# VPE_VPDMA register map
Vendor: Texas Instruments
Registers are 32-bit, access per field, reset 0x0 unless marked. A register's access mark holds for its fields unless they carry their own. Offsets are as the file gives them; [hi:lo] are bit positions; {n}, {i} and the like mark numbered series.

## VPE_VPDMA (part 2 of 3)
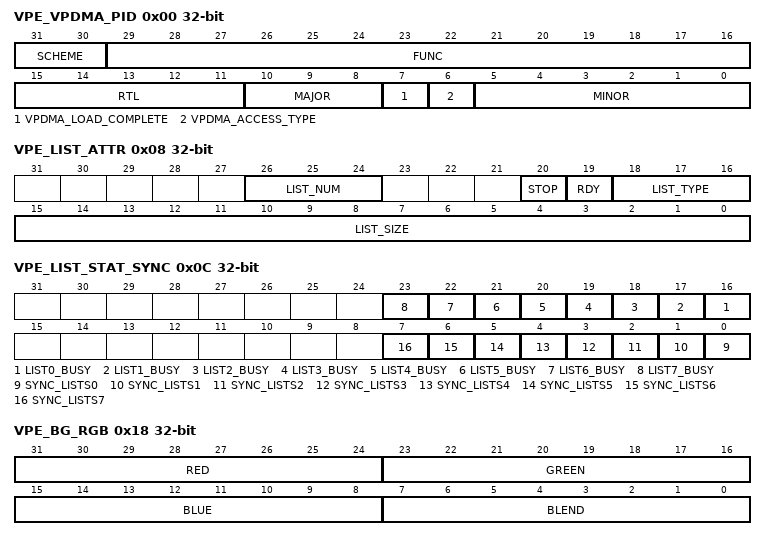
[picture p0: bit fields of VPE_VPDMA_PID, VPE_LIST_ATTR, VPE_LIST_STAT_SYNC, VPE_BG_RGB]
0x00 VPE_VPDMA_PID ro — This register follows the format described in PDR3.5
  [31:30] SCHEME — The scheme of the register used. Currently this is PDR 3.5 Scheme
  [29:16] FUNC — The funcition of the module being used. The value is for vpe0_vayu_vpdma.
  [15:11] RTL — RTL Release Version The PDR release number of this IP. After Bootup this value becomes the firmware Revision ID
  [10:8] MAJOR — Major Release Number
  [7] VPDMA_LOAD_COMPLETE — This bit will be 1 when the VPDMA state machines image and data image have successfuly been fetched and loaded.
  [6] VPDMA_ACCESS_TYPE — After bootup this bit states how DMA transaction are setup by lists or through register access.
    0=Lists; 1=Register_Access
  [5:0] MINOR — Minor Release Number
0x04 VPE_LIST_ADDR rw — The location of a new list to begin processing.
  [31:0] LIST_ADDR — Location of a new list of descriptors. This register must be written with the VPDMA Configuration Location after reset.
0x08 VPE_LIST_ATTR — The attributes of a new list. This register should always be written after list_addr.
  [26:24] LIST_NUM rw — The list number that should be assigned to the list located at LIST_ADDR. If the list is still active this will block all future list writes until the list is available.
  [20] STOP rw — This bit is written with the LIST_NUMBER field to stop a self-modifying list. When this bit is written a one the list specified by the LIST_NUMBER is sent a stop signal and will finish the current frame of transfers and then free the list resources.
  [19] RDY ro — This bit is low when a new list cannot be written to theVPE_LIST_ADDR register. The reasons this bit would be low are at initial startup if the LIST_MANAGER State Machine image has not completed loading. It also would be low if the last write to the LIST_ATTR attempted to start a list that is currently active. When this bit is low any writes to the list address register will cause access to not be accepted until this bit has set by the previous list having completed.
  [18:16] LIST_TYPE rw — The type of list that has been generated.
    0=Normal_List; 1=Self-Modifying_List; 2=List Doorbell Others Reserved for future use
  [15:0] LIST_SIZE rw — Number of 128 bit word in the new list of descriptors. Writes to this register will activate the list in the list stack of the list manager and begin transfer of the list into VPDMA. This size can not be 0.
0x0C VPE_LIST_STAT_SYNC — The register is used for processor to List Manager syncronization and status registers for the list.
  [n+16] LIST{n}_BUSY ro (n=0..7) — The list {n} is currently running. Any attempt to load a new list to list {n} will result in the LM_ADDR and LM_ATTR registers to be locked until the list is complete and this value goes to 0.
  [n] SYNC_LISTS{n} rw (n=0..7) — Writing a 1 to this field causes a sync event to fire that clears a Control Descriptor in List {n} waiting on it.
0x18 VPE_BG_RGB rw — The registers used to set the background color for RGB
  [31:24] RED — The red value to give on an RGB data port for a blank pixel when using virtual video buffering
  [23:16] GREEN — The green value to give on an RGB data port for a blank pixel when using virtual video buffering
  [15:8] BLUE — The blue value to give on an RGB data port for a blank pixel when using virtual video buffering
  [7:0] BLEND — The blend value to give on an RGB data port for a blank pixel when using virtual video buffering
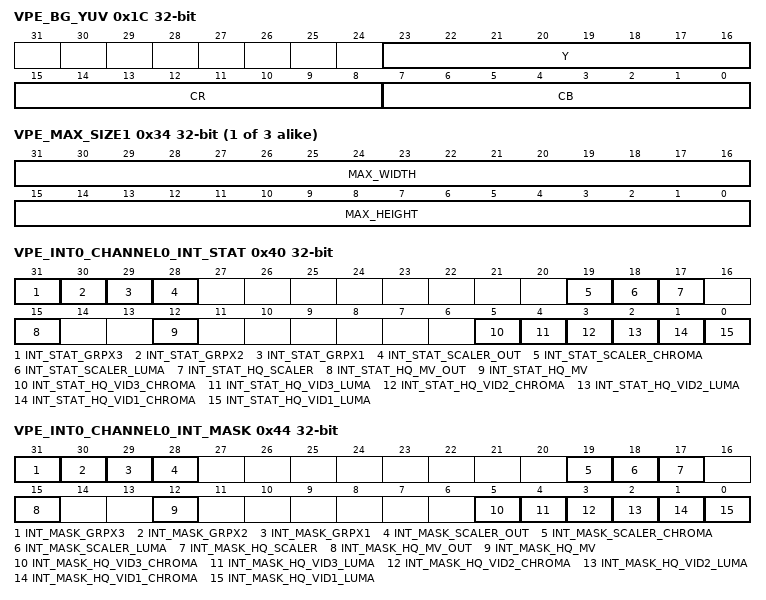
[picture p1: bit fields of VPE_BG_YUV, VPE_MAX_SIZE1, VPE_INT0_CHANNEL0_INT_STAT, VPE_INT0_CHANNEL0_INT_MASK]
0x1C VPE_BG_YUV — The registers used to set the background color for YUV
  [23:16] Y rw — The Y value to give on a YUV data port for a blank pixel when using virtual video buffering
  [15:8] CR rw — The Cr value to give on a YUV data port for a blank pixel when using virtual video buffering
  [7:0] CB rw — The Cb value to give on a YUV data port for a blank pixel when using virtual video buffering
0x30 VPE_VPDMA_SETUP — Configures global parameters that are shared by all clients.
  [0] SEC_BASE_CH rw — Use Secondary Channels for Mosaic mode
{0x30+4i} VPE_MAX_SIZE{i} rw (i=1..3) — Configures maximum width and maximum height global parameters that are shared by all clients to allow for configurable max width and max height when setting is {i} in write descriptor.
  [31:16] MAX_WIDTH — The maximum width to use for setting of max_width {i} in a write descriptor. The value is the number of pixels + 1 so if 1024 pixels are required then set the value to 1023.
  [15:0] MAX_HEIGHT — The maximum height to use for setting of max_height {i} in a write descriptor. The value is the number of lines + 1 so if 1024 lines are required then set the value to 1023.
0x40 VPE_INT0_CHANNEL0_INT_STAT — This register gives the information of the interrupts that have triggered since last cleared by the process that is servicing vpdma_int0.
  [31] INT_STAT_GRPX3 rw — The last read DMA transaction has occurred for channel grpx3 and the channel is free to be updated for the next transfer. This will fire before the destination has received the data as it will have just been stored in the internal buffer. The client grpx3_data will now accept a new descriptor from the List Manager. This event will cause a one to be set in this register until cleared by software. Write a 1 to this field to clear the value.
  [30] INT_STAT_GRPX2 rw — The last read DMA transaction has occurred for channel grpx2 and the channel is free to be updated for the next transfer. This will fire before the destination has received the data as it will have just been stored in the internal buffer. The client grpx2_data will now accept a new descriptor from the List Manager. This event will cause a one to be set in this register until cleared by software. Write a 1 to this field to clear the value.
  [29] INT_STAT_GRPX1 rw — The last read DMA transaction has occurred for channel grpx1 and the channel is free to be updated for the next transfer. This will fire before the destination has received the data as it will have just been stored in the internal buffer. The client grpx1_data will now accept a new descriptor from the List Manager. This event will cause a one to be set in this register until cleared by software. Write a 1 to this field to clear the value.
  [28] INT_STAT_SCALER_OUT rw — The last write DMA transaction has completed for channel scaler_out. All data from the channel has been sent and received by the external memory. If a new channel has not been setup for the client sc_out then the client will be fully empty at this point. This event will cause a one to be set in this register until cleared by software. Write a 1 to this field to clear the value
  [19] INT_STAT_SCALER_CHROMA rw — The last write DMA transaction has completed for channel scaler_chroma. All data from the channel has been sent and received by the external memory. If a new channel has not been setup for the client then the client will be fully empty at this point. This event will cause a one to be set in this register until cleared by software. Write a 1 to this field to clear the value.
  [18] INT_STAT_SCALER_LUMA rw — The last write DMA transaction has completed for channel scaler_luma. All data from the channel has been sent and received by the external memory. If a new channel has not been setup for the client then the client will be fully empty at this point. This event will cause a one to be set in this register until cleared by software. Write a 1 to this field to clear the value.
  [17] INT_STAT_HQ_SCALER rw — The last write DMA transaction has completed for channel hq_scaler. All data from the channel has been sent and received by the external memory. If a new channel has not been setup for the client dei_sc_out then the client will be fully empty at this point. This event will cause a one to be set in this register until cleared by software. Write a 1 to this field to clear the value.
  [15] INT_STAT_HQ_MV_OUT rw — The last write DMA transaction has completed for channel hq_mv_out. All data from the channel has been sent and received by the external memory. If a new channel has not been setup for the client dei_hq_mv_out then the client will be fully empty at this point. This event will cause a one to be set in this register until cleared by software. Write a 1 to this field to clear the value.
  [12] INT_STAT_HQ_MV rw — The last read DMA transaction has occurred for channel hq_mv and the channel is free to be updated for the next transfer. This will fire before the destination has received the data as it will have just been stored in the internal buffer. The client dei_hq_mv_in will now accept a new descriptor from the List Manager. This event will cause a one to be set in this register until cleared by software. Write a 1 to this field to clear the value.
  [5] INT_STAT_HQ_VID3_CHROMA rw — The last write DMA transaction has completed for channel hq_vid3_chroma. All data from the channel has been sent and received by the external memory. If a new channel has not been setup for the client then the client will be fully empty at this point. This event will cause a one to be set in this register until cleared by software. Write a 1 to this field to clear the value.
  [4] INT_STAT_HQ_VID3_LUMA rw — The last write DMA transaction has completed for channel hq_vid3_luma. All data from the channel has been sent and received by the external memory. If a new channel has not been setup for the client then the client will be fully empty at this point. This event will cause a one to be set in this register until cleared by software. Write a 1 to this field to clear the value.
  [3] INT_STAT_HQ_VID2_CHROMA rw — The last write DMA transaction has completed for channel hq_vid2_chroma. All data from the channel has been sent and received by the external memory. If a new channel has not been setup for the client then the client will be fully empty at this point. This event will cause a one to be set in this register until cleared by software. Write a 1 to this field to clear the value.
  [2] INT_STAT_HQ_VID2_LUMA rw — The last write DMA transaction has completed for channel hq_vid2_luma. All data from the channel has been sent and received by the external memory. If a new channel has not been setup for the client then the client will be fully empty at this point. This event will cause a one to be set in this register until cleared by software. Write a 1 to this field to clear the value.
  [1] INT_STAT_HQ_VID1_CHROMA rw — The last write DMA transaction has completed for channel hq_vid1_chroma. All data from the channel has been sent and received by the external memory. If a new channel has not been setup for the client then the client will be fully empty at this point. This event will cause a one to be set in this register until cleared by software. Write a 1 to this field to clear the value.
  [0] INT_STAT_HQ_VID1_LUMA rw — The last write DMA transaction has completed for channel hq_vid1_luma. All data from the channel has been sent and received by the external memory. If a new channel has not been setup for the client then the client will be fully empty at this point. This event will cause a one to be set in this register until cleared by software. Write a 1 to this field to clear the value.
0x44 VPE_INT0_CHANNEL0_INT_MASK — The register gives the information of the interrupts that should be masked and not generate an interrupt for vpdma_int0.
  [31] INT_MASK_GRPX3 rw — The interrupt for Graphcis 2 Data should generate an interrupt on interrupt vpdma_int0. Write a 1 for the interrupt event to trigger the interrupt signal.
  [30] INT_MASK_GRPX2 rw — The interrupt for Graphics 1 Data should generate an interrupt on interrupt vpdma_int0. Write a 1 for the interrupt event to trigger the interrupt signal.
  [29] INT_MASK_GRPX1 rw — The interrupt for Graphics 0 Data should generate an interrupt on interrupt vpdma_int0. Write a 1 for the interrupt event to trigger the interrupt signal.
  [28] INT_MASK_SCALER_OUT rw — The interrupt for Low Cost DEI Scalar Write to Memory should generate an interrupt on interrupt vpdma_int0. Write a 1 for the interrupt event to trigger the interrupt signal.
  [19] INT_MASK_SCALER_CHROMA rw — The interrupt for should generate an interrupt on interrupt vpdma_int0. Write a 1 for the interrupt event to trigger the interrupt signal.
  [18] INT_MASK_SCALER_LUMA rw — The interrupt for should generate an interrupt on interrupt vpdma_int0. Write a 1 for the interrupt event to trigger the interrupt signal.
  [17] INT_MASK_HQ_SCALER rw — The interrupt for High Quality DEI Scaler Write to Memory should generate an interrupt on interrupt vpdma_int0. Write a 1 for the interrupt event to trigger the interrupt signal.
  [15] INT_MASK_HQ_MV_OUT rw — The interrupt for Low Cost DEI Motion Vector Write should generate an interrupt on interrupt vpdma_int0. Write a 1 for the interrupt event to trigger the interrupt signal.
  [12] INT_MASK_HQ_MV rw — The interrupt for Low Cost DEI Motion Vector should generate an interrupt on interrupt vpdma_int0. Write a 1 for the interrupt event to trigger the interrupt signal.
  [5] INT_MASK_HQ_VID3_CHROMA rw — The interrupt for should generate an interrupt on interrupt vpdma_int0. Write a 1 for the interrupt event to trigger the interrupt signal.
  [4] INT_MASK_HQ_VID3_LUMA rw — The interrupt for should generate an interrupt on interrupt vpdma_int0. Write a 1 for the interrupt event to trigger the interrupt signal.
  [3] INT_MASK_HQ_VID2_CHROMA rw — The interrupt for should generate an interrupt on interrupt vpdma_int0. Write a 1 for the interrupt event to trigger the interrupt signal.
  [2] INT_MASK_HQ_VID2_LUMA rw — The interrupt for should generate an interrupt on interrupt vpdma_int0. Write a 1 for the interrupt event to trigger the interrupt signal.
  [1] INT_MASK_HQ_VID1_CHROMA rw — The interrupt for should generate an interrupt on interrupt vpdma_int0. Write a 1 for the interrupt event to trigger the interrupt signal.
  [0] INT_MASK_HQ_VID1_LUMA rw — The interrupt for should generate an interrupt on interrupt vpdma_int0. Write a 1 for the interrupt event to trigger the interrupt signal.
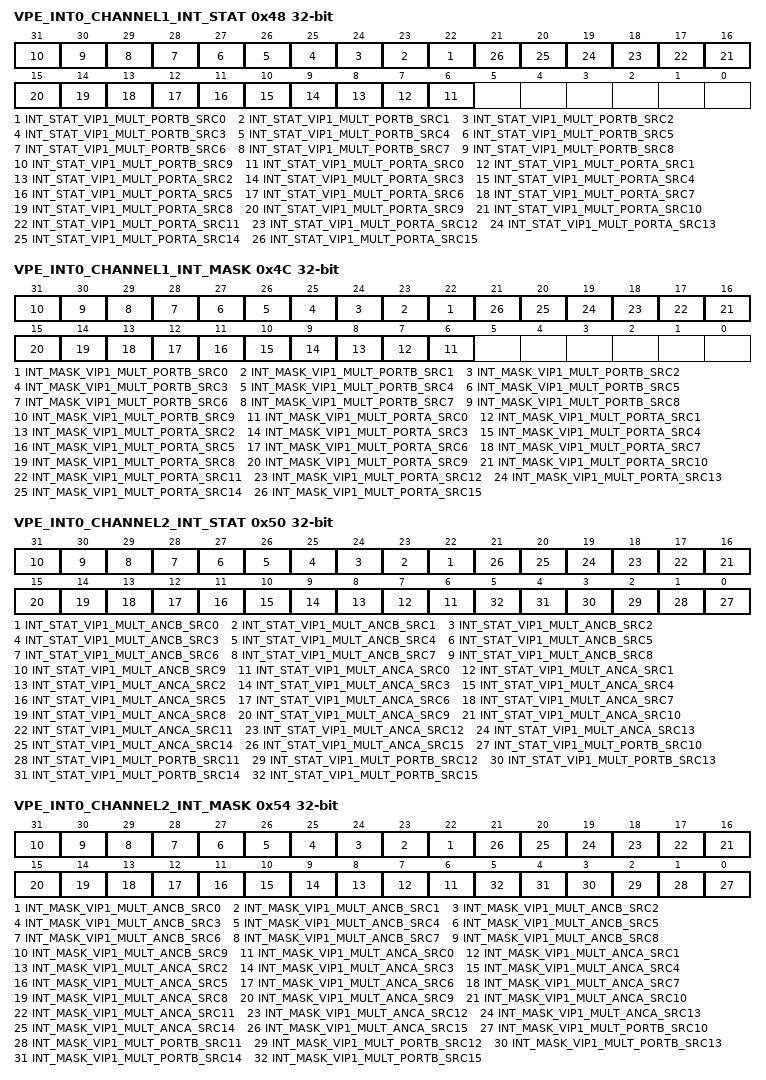
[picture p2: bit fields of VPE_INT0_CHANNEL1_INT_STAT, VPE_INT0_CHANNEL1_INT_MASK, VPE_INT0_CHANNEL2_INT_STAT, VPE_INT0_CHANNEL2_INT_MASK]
0x48 VPE_INT0_CHANNEL1_INT_STAT — This register gives the information of the interrupts that have triggered since last cleared by the process that is servicing vpdma_int0.
  [n+22] INT_STAT_VIP1_MULT_PORTB_SRC{n} rw (n=0..9) — The last write DMA transaction has completed for channel vip1_mult_portb_src{n}. All data from the channel has been sent and received by the external memory. If a new channel has not been setup for the client vip1_lo_uv then the client will be fully empty at this point. This event will cause a one to be set in this register until cleared by software. Write a 1 to this field to clear the value.
  [n+6] INT_STAT_VIP1_MULT_PORTA_SRC{n} rw (n=0..15) — The last write DMA transaction has completed for channel vip1_mult_porta_src{n}. All data from the channel has been sent and received by the external memory. If a new channel has not been setup for the client vip1_lo_y then the client will be fully empty at this point. This event will cause a one to be set in this register until cleared by software. Write a 1 to this field to clear the value.
0x4C VPE_INT0_CHANNEL1_INT_MASK — The register gives the information of the interrupts that should be masked and not generate an interrupt for vpdma_int0.
  [n+22] INT_MASK_VIP1_MULT_PORTB_SRC{n} rw (n=0..9) — The interrupt for Video Input 1 Port B Channel {n} should generate an interrupt on interrupt vpdma_int0. Write a 1 for the interrupt event to trigger the interrupt signal.
  [n+6] INT_MASK_VIP1_MULT_PORTA_SRC{n} rw (n=0..15) — The interrupt for Video Input 1 Port A Channel {n} should generate an interrupt on interrupt vpdma_int0. Write a 1 for the interrupt event to trigger the interrupt signal.
0x50 VPE_INT0_CHANNEL2_INT_STAT rw — This register gives the information of the interrupts that have triggered since last cleared by the process that is servicing vpdma_int0.
  [n+22] INT_STAT_VIP1_MULT_ANCB_SRC{n} (n=0..9) — The last write DMA transaction has completed for channel vip1_mult_ancb_src{n}. All data from the channel has been sent and received by the external memory. If a new channel has not been setup for the client vip1_anc_b then the client will be fully empty at this point. This event will cause a one to be set in this register until cleared by software. Write a 1 to this field to clear the value.
  [n+6] INT_STAT_VIP1_MULT_ANCA_SRC{n} (n=0..15) — The last write DMA transaction has completed for channel vip1_mult_anca_src{n}. All data from the channel has been sent and received by the external memory. If a new channel has not been setup for the client vip1_anc_a then the client will be fully empty at this point. This event will cause a one to be set in this register until cleared by software. Write a 1 to this field to clear the value.
  [n-10] INT_STAT_VIP1_MULT_PORTB_SRC{n} (n=10..15) — The last write DMA transaction has completed for channel vip1_mult_portb_src{n}. All data from the channel has been sent and received by the external memory. If a new channel has not been setup for the client vip1_lo_uv then the client will be fully empty at this point. This event will cause a one to be set in this register until cleared by software. Write a 1 to this field to clear the value.
0x54 VPE_INT0_CHANNEL2_INT_MASK rw — The register gives the information of the interrupts that should be masked and not generate an interrupt for vpdma_int0.
  [n+22] INT_MASK_VIP1_MULT_ANCB_SRC{n} (n=0..9) — The interrupt for Video Input 1 Port B Ancillary Data Channel {n} should generate an interrupt on interrupt vpdma_int0. Write a 1 for the interrupt event to trigger the interrupt signal.
  [n+6] INT_MASK_VIP1_MULT_ANCA_SRC{n} (n=0..15) — The interrupt for Video Input 1 Port A Ancillary Data Channel {n} should generate an interrupt on interrupt vpdma_int0. Write a 1 for the interrupt event to trigger the interrupt signal.
  [n-10] INT_MASK_VIP1_MULT_PORTB_SRC{n} (n=10..15) — The interrupt for Video Input 1 Port B Channel {n} should generate an interrupt on interrupt vpdma_int0. Write a 1 for the interrupt event to trigger the interrupt signal.
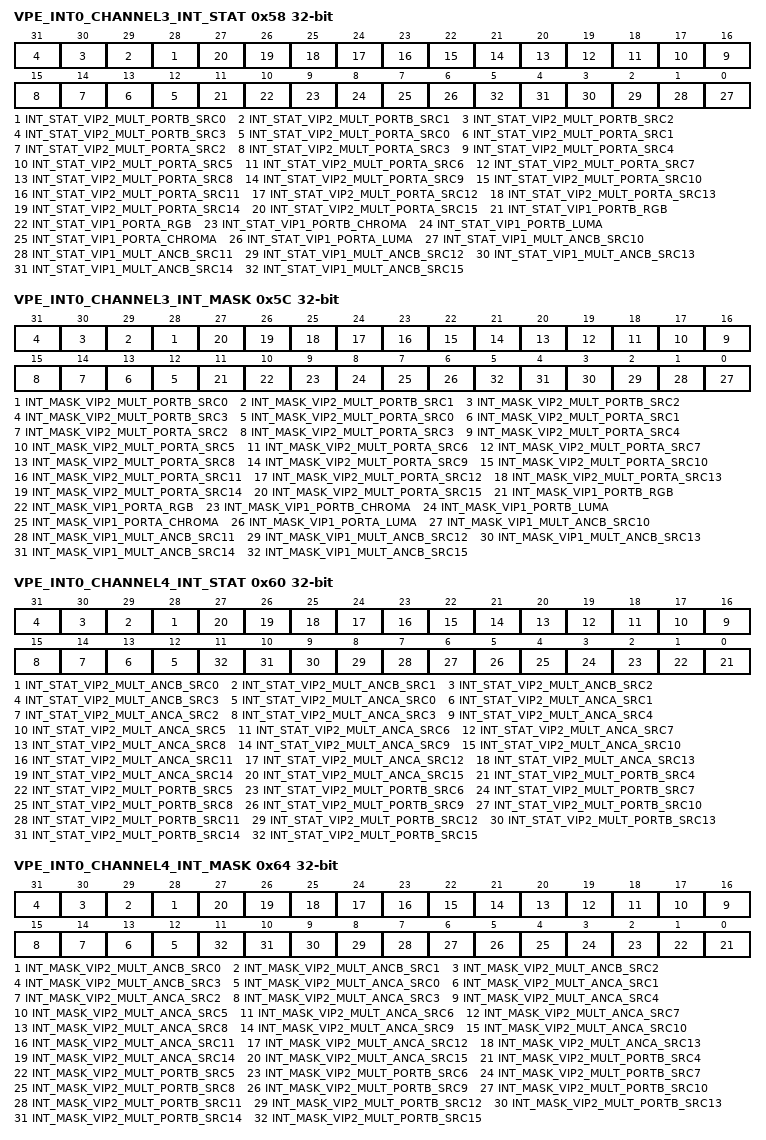
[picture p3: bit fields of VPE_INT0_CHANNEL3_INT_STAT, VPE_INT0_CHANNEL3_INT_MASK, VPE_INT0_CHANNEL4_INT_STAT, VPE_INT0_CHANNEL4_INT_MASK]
0x58 VPE_INT0_CHANNEL3_INT_STAT rw — This register gives the information of the interrupts that have triggered since last cleared by the process that is servicing vpdma_int0.
  [n+28] INT_STAT_VIP2_MULT_PORTB_SRC{n} (n=0..3) — The last write DMA transaction has completed for channel vip2_mult_portb_src{n}. All data from the channel has been sent and received by the external memory. If a new channel has not been setup for the client vip2_lo_uv then the client will be fully empty at this point. This event will cause a one to be set in this register until cleared by software. Write a 1 to this field to clear the value.
  [n+12] INT_STAT_VIP2_MULT_PORTA_SRC{n} (n=0..15) — The last write DMA transaction has completed for channel vip2_mult_porta_src{n}. All data from the channel has been sent and received by the external memory. If a new channel has not been setup for the client vip2_lo_y then the client will be fully empty at this point. This event will cause a one to be set in this register until cleared by software. Write a 1 to this field to clear the value.
  [11] INT_STAT_VIP1_PORTB_RGB — The last write DMA transaction has completed for channel vip1_portb_rgb. All data from the channel has been sent and received by the external memory. If a new channel has not been setup for the client vip1_lo_y then the client will be fully empty at this point. This event will cause a one to be set in this register until cleared by software. Write a 1 to this field to clear the value.
  [10] INT_STAT_VIP1_PORTA_RGB — The last write DMA transaction has completed for channel vip1_porta_rgb. All data from the channel has been sent and received by the external memory. If a new channel has not been setup for the client vip1_up_y then the client will be fully empty at this point. This event will cause a one to be set in this register until cleared by software. Write a 1 to this field to clear the value.
  [9] INT_STAT_VIP1_PORTB_CHROMA — The last write DMA transaction has completed for channel vip1_portb_chroma. All data from the channel has been sent and received by the external memory. If a new channel has not been setup for the client then the client will be fully empty at this point. This event will cause a one to be set in this register until cleared by software. Write a 1 to this field to clear the value.
  [8] INT_STAT_VIP1_PORTB_LUMA — The last write DMA transaction has completed for channel vip1_portb_luma. All data from the channel has been sent and received by the external memory. If a new channel has not been setup for the client then the client will be fully empty at this point. This event will cause a one to be set in this register until cleared by software. Write a 1 to this field to clear the value.
  [7] INT_STAT_VIP1_PORTA_CHROMA — The last write DMA transaction has completed for channel vip1_porta_chroma. All data from the channel has been sent and received by the external memory. If a new channel has not been setup for the client then the client will be fully empty at this point. This event will cause a one to be set in this register until cleared by software. Write a 1 to this field to clear the value.
  [6] INT_STAT_VIP1_PORTA_LUMA — The last write DMA transaction has completed for channel vip1_porta_luma. All data from the channel has been sent and received by the external memory. If a new channel has not been setup for the client then the client will be fully empty at this point. This event will cause a one to be set in this register until cleared by software. Write a 1 to this field to clear the value.
  [n-10] INT_STAT_VIP1_MULT_ANCB_SRC{n} (n=10..15) — The last write DMA transaction has completed for channel vip1_mult_ancb_src{n}. All data from the channel has been sent and received by the external memory. If a new channel has not been setup for the client vip1_anc_b then the client will be fully empty at this point. This event will cause a one to be set in this register until cleared by software. Write a 1 to this field to clear the value.
0x5C VPE_INT0_CHANNEL3_INT_MASK rw — The register gives the information of the interrupts that should be masked and not generate an interrupt for vpdma_int0.
  [n+28] INT_MASK_VIP2_MULT_PORTB_SRC{n} (n=0..3) — The interrupt for Video Input 2 Port B Channel {n} should generate an interrupt on interrupt vpdma_int0. Write a 1 for the interrupt event to trigger the interrupt signal.
  [n+12] INT_MASK_VIP2_MULT_PORTA_SRC{n} (n=0..15) — The interrupt for Video Input 2 Port A Channel {n} should generate an interrupt on interrupt vpdma_int0. Write a 1 for the interrupt event to trigger the interrupt signal.
  [11] INT_MASK_VIP1_PORTB_RGB — The interrupt for Video Input 1 Port B RGB Data should generate an interrupt on interrupt vpdma_int0. Write a 1 for the interrupt event to trigger the interrupt signal.
  [10] INT_MASK_VIP1_PORTA_RGB — The interrupt for Video Input 1 Port A RGB Data should generate an interrupt on interrupt vpdma_int0. Write a 1 for the interrupt event to trigger the interrupt signal.
  [9] INT_MASK_VIP1_PORTB_CHROMA — The interrupt for should generate an interrupt on interrupt vpdma_int0. Write a 1 for the interrupt event to trigger the interrupt signal.
  [8] INT_MASK_VIP1_PORTB_LUMA — The interrupt for should generate an interrupt on interrupt vpdma_int0. Write a 1 for the interrupt event to trigger the interrupt signal.
  [7] INT_MASK_VIP1_PORTA_CHROMA — The interrupt for should generate an interrupt on interrupt vpdma_int0. Write a 1 for the interrupt event to trigger the interrupt signal.
  [6] INT_MASK_VIP1_PORTA_LUMA — The interrupt for should generate an interrupt on interrupt vpdma_int0. Write a 1 for the interrupt event to trigger the interrupt signal.
  [n-10] INT_MASK_VIP1_MULT_ANCB_SRC{n} (n=10..15) — The interrupt for Video Input 1 Port B Ancillary Data Channel {n} should generate an interrupt on interrupt vpdma_int0. Write a 1 for the interrupt event to trigger the interrupt signal.
0x60 VPE_INT0_CHANNEL4_INT_STAT rw — This register gives the information of the interrupts that have triggered since last cleared by the process that is servicing vpdma_int0.
  [n+28] INT_STAT_VIP2_MULT_ANCB_SRC{n} (n=0..3) — The last write DMA transaction has completed for channel vip2_mult_ancb_src{n}. All data from the channel has been sent and received by the external memory. If a new channel has not been setup for the client vip2_anc_b then the client will be fully empty at this point. This event will cause a one to be set in this register until cleared by software. Write a 1 to this field to clear the value.
  [n+12] INT_STAT_VIP2_MULT_ANCA_SRC{n} (n=0..15) — The last write DMA transaction has completed for channel vip2_mult_anca_src{n}. All data from the channel has been sent and received by the external memory. If a new channel has not been setup for the client vip2_anc_a then the client will be fully empty at this point. This event will cause a one to be set in this register until cleared by software. Write a 1 to this field to clear the value.
  [n-4] INT_STAT_VIP2_MULT_PORTB_SRC{n} (n=4..15) — The last write DMA transaction has completed for channel vip2_mult_portb_src{n}. All data from the channel has been sent and received by the external memory. If a new channel has not been setup for the client vip2_lo_uv then the client will be fully empty at this point. This event will cause a one to be set in this register until cleared by software. Write a 1 to this field to clear the value.
0x64 VPE_INT0_CHANNEL4_INT_MASK rw — The register gives the information of the interrupts that should be masked and not generate an interrupt for vpdma_int0.
  [n+28] INT_MASK_VIP2_MULT_ANCB_SRC{n} (n=0..3) — The interrupt for Video Input 2 Port B Ancillary Data Channel {n} should generate an interrupt on interrupt vpdma_int0. Write a 1 for the interrupt event to trigger the interrupt signal.
  [n+12] INT_MASK_VIP2_MULT_ANCA_SRC{n} (n=0..15) — The interrupt for Video Input 2 Port A Ancillary Data Channel {n} should generate an interrupt on interrupt vpdma_int0. Write a 1 for the interrupt event to trigger the interrupt signal.
  [n-4] INT_MASK_VIP2_MULT_PORTB_SRC{n} (n=4..15) — The interrupt for Video Input 2 Port B Channel {n} should generate an interrupt on interrupt vpdma_int0. Write a 1 for the interrupt event to trigger the interrupt signal.
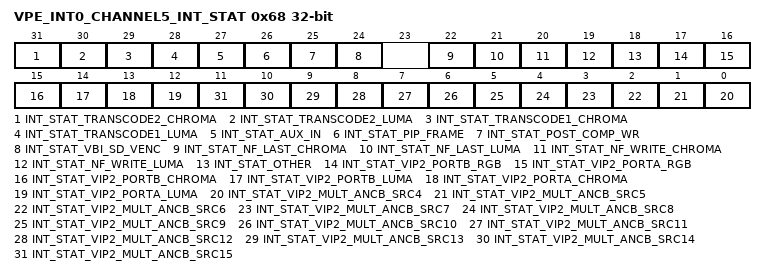
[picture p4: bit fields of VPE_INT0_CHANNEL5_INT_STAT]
0x68 VPE_INT0_CHANNEL5_INT_STAT — This register gives the information of the interrupts that have triggered since last cleared by the process that is servicing vpdma_int0.
  [31] INT_STAT_TRANSCODE2_CHROMA rw — The last write DMA transaction has completed for channel transcode2_chroma. All data from the channel has been sent and received by the external memory. If a new channel has not been setup for the client then the client will be fully empty at this point. This event will cause a one to be set in this register until cleared by software. Write a 1 to this field to clear the value.
  [30] INT_STAT_TRANSCODE2_LUMA rw — The last write DMA transaction has completed for channel transcode2_luma. All data from the channel has been sent and received by the external memory. If a new channel has not been setup for the client then the client will be fully empty at this point. This event will cause a one to be set in this register until cleared by software. Write a 1 to this field to clear the value.
  [29] INT_STAT_TRANSCODE1_CHROMA rw — The last write DMA transaction has completed for channel transcode1_luma. All data from the channel has been sent and received by the external memory. If a new channel has not been setup for the client then the client will be fully empty at this point. This event will cause a one to be set in this register until cleared by software. Write a 1 to this field to clear the value.
  [28] INT_STAT_TRANSCODE1_LUMA rw — The last write DMA transaction has completed for channel transcode1_luma. All data from the channel has been sent and received by the external memory. If a new channel has not been setup for the client then the client will be fully empty at this point. This event will cause a one to be set in this register until cleared by software. Write a 1 to this field to clear the value.
  [27] INT_STAT_AUX_IN rw — The last read DMA transaction has occurred for channel aux_in and the channel is free to be updated for the next transfer. This will fire before the destination has received the data as it will have just been stored in the internal buffer. The client comp_wrbk will now accept a new descriptor from the List Manager. This event will cause a one to be set in this register until cleared by software. Write a 1 to this field to clear the value.
  [26] INT_STAT_PIP_FRAME rw — The last read DMA transaction has occurred for channel pip_frame and the channel is free to be updated for the next transfer. This will fire before the destination has received the data as it will have just been stored in the internal buffer. The client pip_wrbk will now accept a new descriptor from the List Manager. This event will cause a one to be set in this register until cleared by software. Write a 1 to this field to clear the value.
  [25] INT_STAT_POST_COMP_WR rw — The last write DMA transaction has completed for channel post_comp_wr. All data from the channel has been sent and received by the external memory. If a new channel has not been setup for the client hdmi_wrbk_out then the client will be fully empty at this point. This event will cause a one to be set in this register until cleared by software. Write a 1 to this field to clear the value.
  [24] INT_STAT_VBI_SD_VENC rw — The last read DMA transaction has occurred for channel vbi_sd_venc and the channel is free to be updated for the next transfer. This will fire before the destination has received the data as it will have just been stored in the internal buffer. The client vbi_sdvenc will now accept a new descriptor from the List Manager. This event will cause a one to be set in this register until cleared by software. Write a 1 to this field to clear the value.
  [22] INT_STAT_NF_LAST_CHROMA rw — The last write DMA transaction has completed for channel nf_last_chroma. All data from the channel has been sent and received by the external memory. If a new channel has not been setup for the client then the client will be fully empty at this point. This event will cause a one to be set in this register until cleared by software. Write a 1 to this field to clear the value.
  [21] INT_STAT_NF_LAST_LUMA rw — The last write DMA transaction has completed for channel nf_last_luma. All data from the channel has been sent and received by the external memory. If a new channel has not been setup for the client then the client will be fully empty at this point. This event will cause a one to be set in this register until cleared by software. Write a 1 to this field to clear the value.
  [20] INT_STAT_NF_WRITE_CHROMA rw — The last write DMA transaction has completed for channel nf_write_chroma. All data from the channel has been sent and received by the external memory. If a new channel has not been setup for the client then the client will be fully empty at this point. This event will cause a one to be set in this register until cleared by software. Write a 1 to this field to clear the value.
  [19] INT_STAT_NF_WRITE_LUMA rw — The last write DMA transaction has completed for channel nf_write_luma. All data from the channel has been sent and received by the external memory. If a new channel has not been setup for the client then the client will be fully empty at this point. This event will cause a one to be set in this register until cleared by software. Write a 1 to this field to clear the value.
  [18] INT_STAT_OTHER rw — This event will cause a one to be set in this register until cleared by software. Write a 1 to this field to clear the value.
  [17] INT_STAT_VIP2_PORTB_RGB rw — The last write DMA transaction has completed for channel vip2_portb_rgb. All data from the channel has been sent and received by the external memory. If a new channel has not been setup for the client vip2_lo_y then the client will be fully empty at this point. This event will cause a one to be set in this register until cleared by software. Write a 1 to this field to clear the value.
  [16] INT_STAT_VIP2_PORTA_RGB rw — The last write DMA transaction has completed for channel vip2_porta_rgb. All data from the channel has been sent and received by the external memory. If a new channel has not been setup for the client vip2_up_y then the client will be fully empty at this point. This event will cause a one to be set in this register until cleared by software. Write a 1 to this field to clear the value.
  [15] INT_STAT_VIP2_PORTB_CHROMA rw — The last write DMA transaction has completed for channel vip2_portb_chroma. All data from the channel has been sent and received by the external memory. If a new channel has not been setup for the client then the client will be fully empty at this point. This event will cause a one to be set in this register until cleared by software. Write a 1 to this field to clear the value.
  [14] INT_STAT_VIP2_PORTB_LUMA rw — The last write DMA transaction has completed for channel vip2_portb_luma. All data from the channel has been sent and received by the external memory. If a new channel has not been setup for the client then the client will be fully empty at this point. This event will cause a one to be set in this register until cleared by software. Write a 1 to this field to clear the value.
  [13] INT_STAT_VIP2_PORTA_CHROMA rw — The last write DMA transaction has completed for channel vip2_porta_chroma. All data from the channel has been sent and received by the external memory. If a new channel has not been setup for the client then the client will be fully empty at this point. This event will cause a one to be set in this register until cleared by software. Write a 1 to this field to clear the value.
  [12] INT_STAT_VIP2_PORTA_LUMA rw — The last write DMA transaction has completed for channel vip2_porta_luma. All data from the channel has been sent and received by the external memory. If a new channel has not been setup for the client then the client will be fully empty at this point. This event will cause a one to be set in this register until cleared by software. Write a 1 to this field to clear the value.
  [n-4] INT_STAT_VIP2_MULT_ANCB_SRC{n} rw (n=4..15) — The last write DMA transaction has completed for channel vip2_mult_ancb_src{n}. All data from the channel has been sent and received by the external memory. If a new channel has not been setup for the client vip2_anc_b then the client will be fully empty at this point. This event will cause a one to be set in this register until cleared by software. Write a 1 to this field to clear the value.
